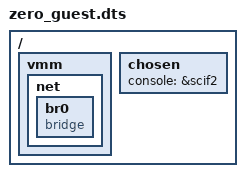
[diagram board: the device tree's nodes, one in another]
/dts-v1/;

#include "./r8a7795-salvator-x.dtsi"

/ {
        vmm {
                net {
                        br0 {
                                device_type = "netswitch";
                                compatible = "bridge";
                        };
                };
        };

        chosen {
                console = &scif2;
        };
};
